AUTOSAR XML (schema 00044)
package /E40_Platform_System_SystemPackage/Components
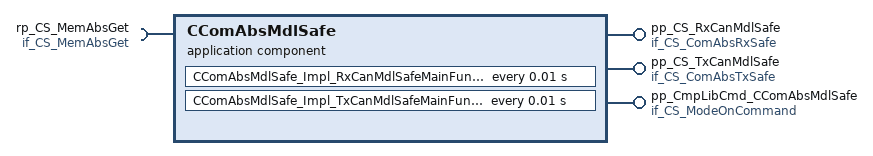
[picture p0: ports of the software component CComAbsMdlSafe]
  application sw component type CComAbsMdlSafe
    provide port pp_CS_RxCanMdlSafe: provided-interface=if_CS_ComAbsRxSafe
      provided-com-specs:
        operation=RxCan_GetSignalValue, queue-length=1
        operation=RxCan_GetSignalValueU8Arr, queue-length=1
        operation=RxCan_SetSignalInitValue, queue-length=1
        operation=RxCan_SetSignalInitValueU8Arr, queue-length=1
        operation=RxCan_SignalClearJustRcvdStatus, queue-length=1
        operation=RxCan_SignalGetJustRcvdStatus, queue-length=1
        operation=RxCan_SignalInvalidProcessingControl, queue-length=1
        operation=RxCan_SignalMissingProcessingControl, queue-length=1
        operation=RxCan_SignalNRProcessingControl, queue-length=1
    provide port pp_CS_TxCanMdlSafe: provided-interface=if_CS_ComAbsTxSafe
      provided-com-specs:
        operation=TxCan_ClearCanSignalTxConfirmation, queue-length=1
        operation=TxCan_GetCanSignalTxConfirmation, queue-length=1
        operation=TxCan_SetSignalFromRetentionBuffer, queue-length=1
        operation=TxCan_SetSignalValue, queue-length=1
        operation=TxCan_SetSignalValueU8Arr, queue-length=1
    provide port pp_CmpLibCmd_CComAbsMdlSafe: server-com-spec{operation=Impl_OnCommand, queue-length=1}, provided-interface=if_CS_ModeOnCommand
    require port rp_CS_MemAbsGet: required-interface=if_CS_MemAbsGet
      required-com-specs:
        Get_BsConst_Audio_Element
        Get_BsConst_Communication_Element
        Get_BsConst_EngOffTimer_Element
        Get_BsConst_FuelGauge_Element
        Get_BsConst_OilGauge_Element
        Get_BsConst_PowerGauge_Element
        Get_BsConst_Power_Element
        Get_BsConst_RealTimeClock_Element
        Get_BsConst_ServiceReminder_Element
        Get_BsConst_SpeedoGauge_Element
        Get_BsConst_TachoGauge_Element
        Get_BsConst_TempGauge_Element
        Get_BsConst_TripComputer_Element
        Get_BsConst_Warning_Element
        Get_BsCys_Certicificate_Element
        Get_BsDiag_Dtc_Element
        Get_BsDiag_ErrorRecord_Element
        Get_BsReten_Audio_Element
        Get_BsReten_Communication_Element
        Get_BsReten_Display_Element
        Get_BsReten_Gauges_Element
        Get_BsReten_Illumination_Element
        Get_BsReten_Odometer_Element
        Get_BsReten_Personalization_Element
        Get_BsReten_Power_Element
        Get_BsReten_RealTimeClock_Element
        Get_BsReten_Tripcomputer_Element
        Get_BsReten_Warning_Element
        Get_BsRt_CusDlt_Element
        Get_BsRt_FuelGauge_Element
        Get_BsRt_Illumination_Element
        Get_BsRt_Odometer_Element
        Get_BsRt_OilGauge_Element
        Get_BsRt_Personalization_Element
        Get_BsRt_PowerGauge_Element
        Get_BsRt_RealTimeClock_Element
        Get_BsRt_SpeedoGauge_Element
        Get_BsRt_TachoGauge_Element
        Get_BsRt_TempGauge_Element
        Get_BsRt_TripComputer_Element
        Get_BsRt_Warning_Element
        Get_BsShare_EcuPartNumber_Element
        Get_BsShare_SwUpdFotaFinPrint_Element
        Get_BsShare_SwUpdFotaMode_Element
        Get_BsShare_SwUpdFotaStatus_Element
        Get_BsShare_SwUpdFotadecrypt_Element
        Get_BsShare_SwUpdReflash_Element
        Get_BsShare_VehicleConfig_Element
        Get_BsShare_VisMeet_Element
        Get_RefCys_Certicificate1_Element
        Get_RefCys_Certicificate_Element
        Get_BsShare_VisMeet_EOLEntry_Element
        Get_BsShare_AssemblyManufacturingDate
        Get_BsShare_AssemblyPlantNumber
        Get_BsShare_HWModification
        Get_BsShare_PCBSerialNumber
        Get_BsShare_ProductSerialNumber
        Get_BsShare_SMTManufacturingDate
        Get_BsShare_SMTPlantNumber
        Get_BsShare_VisteonPCBPartNumber
        Get_BsShare_VisteonPartNumber
        Get_BsConst_BsConst_Illumination_ReservedByte
        Get_BsConst_BsConst_Illumination_ReservedByte_SafeCopy1
        Get_BsConst_BsConst_Illumination_ReservedByte_SafeCopy2
        Get_BsConst_Compensation_Line_Shift_b
        Get_BsConst_Compensation_Line_Shift_b_SafeCopy1
        Get_BsConst_Compensation_Line_Shift_b_SafeCopy2
        Get_BsConst_Compensation_Line_Slope_m
        Get_BsConst_Compensation_Line_Slope_m_SafeCopy1
        Get_BsConst_Compensation_Line_Slope_m_SafeCopy2
        Get_BsConst_Derating_Backlight_Disable
        Get_BsConst_Derating_Backlight_Disable_SafeCopy1
        Get_BsConst_Derating_Backlight_Disable_SafeCopy2
        Get_BsConst_Display_Illum_Max_Level
        Get_BsConst_Display_Illum_Max_Level_SafeCopy1
        Get_BsConst_Display_Illum_Max_Level_SafeCopy2
        Get_BsConst_Lookup_Curve_HotSpot_Coef_X
        Get_BsConst_Lookup_Curve_HotSpot_Coef_X_SafeCopy1
        Get_BsConst_Lookup_Curve_HotSpot_Coef_X_SafeCopy2
        Get_BsConst_Lookup_Curve_HotSpot_Coef_Y
        Get_BsConst_Lookup_Curve_HotSpot_Coef_Y_SafeCopy1
        Get_BsConst_Lookup_Curve_HotSpot_Coef_Y_SafeCopy2
        Get_BsConst_PCB_Temperature_Sensor_Conv
        Get_BsConst_PCB_Temperature_Sensor_Conv_SafeCopy1
        Get_BsConst_PCB_Temperature_Sensor_Conv_SafeCopy2
        Get_BsConst_PWM_boost_bypass_duty
        Get_BsConst_PWM_boost_bypass_duty_SafeCopy1
        Get_BsConst_PWM_boost_bypass_duty_SafeCopy2
        Get_BsConst_Temp_Threshold_Hysteresis_Derating
        Get_BsConst_Temp_Threshold_Hysteresis_Derating_SafeCopy1
        Get_BsConst_Temp_Threshold_Hysteresis_Derating_SafeCopy2
        Get_BsConst_Temperature_Sensor_Conv
        Get_BsConst_Temperature_Sensor_Conv_SafeCopy1
        Get_BsConst_Temperature_Sensor_Conv_SafeCopy2
    behavior IB_CComAbsMdlSafe
      operation invoked event OIE_pp_CmpLibCmd_CComAbsMdlSafe_CComAbsMdlSafe_Impl_OnCommandTrigByImpl_OnCommand: start-on-event=CComAbsMdlSafe_Impl_OnCommand, operation=pp_CmpLibCmd_CComAbsMdlSafe.Impl_OnCommand
      timing event TECComAbsMdlSafe_Impl_RxCanMdlSafeMainFunction: start-on-event=CComAbsMdlSafe_Impl_RxCanMdlSafeMainFunction, period=0.01
      timing event TECComAbsMdlSafe_Impl_TxCanMdlSafeMainFunction: start-on-event=CComAbsMdlSafe_Impl_TxCanMdlSafeMainFunction, period=0.01
      14 x operation invoked event:
        OIE_pp_CS_RxCanMdlSafe_CComAbsMdlSafe_RxCan_GetSignalValueTrigByRxCan_GetSignalValue: start-on-event=CComAbsMdlSafe_RxCan_GetSignalValue, operation=pp_CS_RxCanMdlSafe.RxCan_GetSignalValue
        OIE_pp_CS_RxCanMdlSafe_CComAbsMdlSafe_RxCan_GetSignalValueU8ArrTrigByRxCan_GetSignalValueU8Arr: start-on-event=CComAbsMdlSafe_RxCan_GetSignalValueU8Arr, operation=pp_CS_RxCanMdlSafe.RxCan_GetSignalValueU8Arr
        OIE_pp_CS_RxCanMdlSafe_CComAbsMdlSafe_RxCan_SetSignalInitValueTrigByRxCan_SetSignalInitValue: start-on-event=CComAbsMdlSafe_RxCan_SetSignalInitValue, operation=pp_CS_RxCanMdlSafe.RxCan_SetSignalInitValue
        OIE_pp_CS_RxCanMdlSafe_CComAbsMdlSafe_RxCan_SetSignalInitValueU8ArrTrigByRxCan_SetSignalInitValueU8Arr: start-on-event=CComAbsMdlSafe_RxCan_SetSignalInitValueU8Arr, operation=pp_CS_RxCanMdlSafe.RxCan_SetSignalInitValueU8Arr
        OIE_pp_CS_RxCanMdlSafe_CComAbsMdlSafe_RxCan_SignalClearJustRcvdStatusTrigByRxCan_SignalClearJustRcvdStatus: start-on-event=CComAbsMdlSafe_RxCan_SignalClearJustRcvdStatus, operation=pp_CS_RxCanMdlSafe.RxCan_SignalClearJustRcvdStatus
        OIE_pp_CS_RxCanMdlSafe_CComAbsMdlSafe_RxCan_SignalGetJustRcvdStatusTrigByRxCan_SignalGetJustRcvdStatus: start-on-event=CComAbsMdlSafe_RxCan_SignalGetJustRcvdStatus, operation=pp_CS_RxCanMdlSafe.RxCan_SignalGetJustRcvdStatus
        OIE_pp_CS_RxCanMdlSafe_CComAbsMdlSafe_RxCan_SignalInvalidProcessingControlTrigByRxCan_SignalInvalidProcessingControl: start-on-event=CComAbsMdlSafe_RxCan_SignalInvalidProcessingControl, operation=pp_CS_RxCanMdlSafe.RxCan_SignalInvalidProcessingControl
        OIE_pp_CS_RxCanMdlSafe_CComAbsMdlSafe_RxCan_SignalMissingProcessingControlTrigByRxCan_SignalMissingProcessingControl: start-on-event=CComAbsMdlSafe_RxCan_SignalMissingProcessingControl, operation=pp_CS_RxCanMdlSafe.RxCan_SignalMissingProcessingControl
        OIE_pp_CS_RxCanMdlSafe_CComAbsMdlSafe_RxCan_SignalNRProcessingControlTrigByRxCan_SignalNRProcessingControl: start-on-event=CComAbsMdlSafe_RxCan_SignalNRProcessingControl, operation=pp_CS_RxCanMdlSafe.RxCan_SignalNRProcessingControl
        OIE_pp_CS_TxCanMdlSafe_CComAbsMdlSafe_TxCan_ClearCanSignalTxConfirmationTrigByTxCan_ClearCanSignalTxConfirmation: start-on-event=CComAbsMdlSafe_TxCan_ClearCanSignalTxConfirmation, operation=pp_CS_TxCanMdlSafe.TxCan_ClearCanSignalTxConfirmation
        OIE_pp_CS_TxCanMdlSafe_CComAbsMdlSafe_TxCan_GetCanSignalTxConfirmationTrigByTxCan_GetCanSignalTxConfirmation: start-on-event=CComAbsMdlSafe_TxCan_GetCanSignalTxConfirmation, operation=pp_CS_TxCanMdlSafe.TxCan_GetCanSignalTxConfirmation
        OIE_pp_CS_TxCanMdlSafe_CComAbsMdlSafe_TxCan_SetSignalFromRetentionBufferTrigByTxCan_SetSignalFromRetentionBuffer: start-on-event=CComAbsMdlSafe_TxCan_SetSignalFromRetentionBuffer, operation=pp_CS_TxCanMdlSafe.TxCan_SetSignalFromRetentionBuffer
        OIE_pp_CS_TxCanMdlSafe_CComAbsMdlSafe_TxCan_SetSignalValueTrigByTxCan_SetSignalValue: start-on-event=CComAbsMdlSafe_TxCan_SetSignalValue, operation=pp_CS_TxCanMdlSafe.TxCan_SetSignalValue
        OIE_pp_CS_TxCanMdlSafe_CComAbsMdlSafe_TxCan_SetSignalValueU8ArrTrigByTxCan_SetSignalValueU8Arr: start-on-event=CComAbsMdlSafe_TxCan_SetSignalValueU8Arr, operation=pp_CS_TxCanMdlSafe.TxCan_SetSignalValueU8Arr
      port-api-options:
        enable-take-address=false, error-handling=NO-TRANSFORMER-ERROR-HANDLING, indirect-api=false, port=pp_CS_RxCanMdlSafe
        enable-take-address=false, error-handling=NO-TRANSFORMER-ERROR-HANDLING, indirect-api=false, port=pp_CS_TxCanMdlSafe
        enable-take-address=false, error-handling=NO-TRANSFORMER-ERROR-HANDLING, indirect-api=false, port=pp_CmpLibCmd_CComAbsMdlSafe
        enable-take-address=false, error-handling=NO-TRANSFORMER-ERROR-HANDLING, indirect-api=false, port=rp_CS_MemAbsGet
      17 x runnable, all with can-be-invoked-concurrently=true:
        CComAbsMdlSafe_Impl_OnCommand
          94 x sync call:
            OA_rp_CS_MemAbsGet_Get_BsShare_SwUpdReflash_Element: operation=rp_CS_MemAbsGet.Get_BsShare_SwUpdReflash_Element
            OA_rp_CS_MemAbsGet_Get_BsShare_SwUpdFotaMode_Element: operation=rp_CS_MemAbsGet.Get_BsShare_SwUpdFotaMode_Element
            OA_rp_CS_MemAbsGet_Get_BsShare_SwUpdFotaFinPrint_Element: operation=rp_CS_MemAbsGet.Get_BsShare_SwUpdFotaFinPrint_Element
            OA_rp_CS_MemAbsGet_Get_BsShare_SwUpdFotaStatus_Element: operation=rp_CS_MemAbsGet.Get_BsShare_SwUpdFotaStatus_Element
            OA_rp_CS_MemAbsGet_Get_BsShare_SwUpdFotadecrypt_Element: operation=rp_CS_MemAbsGet.Get_BsShare_SwUpdFotadecrypt_Element
            OA_rp_CS_MemAbsGet_Get_BsShare_EcuPartNumber_Element: operation=rp_CS_MemAbsGet.Get_BsShare_EcuPartNumber_Element
            OA_rp_CS_MemAbsGet_Get_BsShare_VisteonPartNumber: operation=rp_CS_MemAbsGet.Get_BsShare_VisteonPartNumber
            OA_rp_CS_MemAbsGet_Get_BsShare_VisteonPCBPartNumber: operation=rp_CS_MemAbsGet.Get_BsShare_VisteonPCBPartNumber
            OA_rp_CS_MemAbsGet_Get_BsShare_ProductSerialNumber: operation=rp_CS_MemAbsGet.Get_BsShare_ProductSerialNumber
            OA_rp_CS_MemAbsGet_Get_BsShare_PCBSerialNumber: operation=rp_CS_MemAbsGet.Get_BsShare_PCBSerialNumber
            OA_rp_CS_MemAbsGet_Get_BsShare_SMTManufacturingDate: operation=rp_CS_MemAbsGet.Get_BsShare_SMTManufacturingDate
            OA_rp_CS_MemAbsGet_Get_BsShare_AssemblyManufacturingDate: operation=rp_CS_MemAbsGet.Get_BsShare_AssemblyManufacturingDate
            OA_rp_CS_MemAbsGet_Get_BsShare_SMTPlantNumber: operation=rp_CS_MemAbsGet.Get_BsShare_SMTPlantNumber
            OA_rp_CS_MemAbsGet_Get_BsShare_AssemblyPlantNumber: operation=rp_CS_MemAbsGet.Get_BsShare_AssemblyPlantNumber
            OA_rp_CS_MemAbsGet_Get_BsShare_HWModification: operation=rp_CS_MemAbsGet.Get_BsShare_HWModification
            OA_rp_CS_MemAbsGet_Get_BsShare_VisMeet_Element: operation=rp_CS_MemAbsGet.Get_BsShare_VisMeet_Element
            OA_rp_CS_MemAbsGet_Get_BsShare_VisMeet_EOLEntry_Element: operation=rp_CS_MemAbsGet.Get_BsShare_VisMeet_EOLEntry_Element
            OA_rp_CS_MemAbsGet_Get_BsShare_VehicleConfig_Element: operation=rp_CS_MemAbsGet.Get_BsShare_VehicleConfig_Element
            OA_rp_CS_MemAbsGet_Get_BsConst_SpeedoGauge_Element: operation=rp_CS_MemAbsGet.Get_BsConst_SpeedoGauge_Element
            OA_rp_CS_MemAbsGet_Get_BsConst_TachoGauge_Element: operation=rp_CS_MemAbsGet.Get_BsConst_TachoGauge_Element
            OA_rp_CS_MemAbsGet_Get_BsConst_FuelGauge_Element: operation=rp_CS_MemAbsGet.Get_BsConst_FuelGauge_Element
            OA_rp_CS_MemAbsGet_Get_BsConst_TempGauge_Element: operation=rp_CS_MemAbsGet.Get_BsConst_TempGauge_Element
            OA_rp_CS_MemAbsGet_Get_BsConst_PowerGauge_Element: operation=rp_CS_MemAbsGet.Get_BsConst_PowerGauge_Element
            OA_rp_CS_MemAbsGet_Get_BsConst_OilGauge_Element: operation=rp_CS_MemAbsGet.Get_BsConst_OilGauge_Element
            OA_rp_CS_MemAbsGet_Get_BsConst_TripComputer_Element: operation=rp_CS_MemAbsGet.Get_BsConst_TripComputer_Element
            OA_rp_CS_MemAbsGet_Get_BsConst_Compensation_Line_Slope_m: operation=rp_CS_MemAbsGet.Get_BsConst_Compensation_Line_Slope_m
            OA_rp_CS_MemAbsGet_Get_BsConst_Compensation_Line_Shift_b: operation=rp_CS_MemAbsGet.Get_BsConst_Compensation_Line_Shift_b
            OA_rp_CS_MemAbsGet_Get_BsConst_Lookup_Curve_HotSpot_Coef_X: operation=rp_CS_MemAbsGet.Get_BsConst_Lookup_Curve_HotSpot_Coef_X
            OA_rp_CS_MemAbsGet_Get_BsConst_Lookup_Curve_HotSpot_Coef_Y: operation=rp_CS_MemAbsGet.Get_BsConst_Lookup_Curve_HotSpot_Coef_Y
            OA_rp_CS_MemAbsGet_Get_BsConst_Temp_Threshold_Hysteresis_Derating: operation=rp_CS_MemAbsGet.Get_BsConst_Temp_Threshold_Hysteresis_Derating
            OA_rp_CS_MemAbsGet_Get_BsConst_Derating_Backlight_Disable: operation=rp_CS_MemAbsGet.Get_BsConst_Derating_Backlight_Disable
            OA_rp_CS_MemAbsGet_Get_BsConst_Temperature_Sensor_Conv: operation=rp_CS_MemAbsGet.Get_BsConst_Temperature_Sensor_Conv
            OA_rp_CS_MemAbsGet_Get_BsConst_PCB_Temperature_Sensor_Conv: operation=rp_CS_MemAbsGet.Get_BsConst_PCB_Temperature_Sensor_Conv
            OA_rp_CS_MemAbsGet_Get_BsConst_Display_Illum_Max_Level: operation=rp_CS_MemAbsGet.Get_BsConst_Display_Illum_Max_Level
            OA_rp_CS_MemAbsGet_Get_BsConst_PWM_boost_bypass_duty: operation=rp_CS_MemAbsGet.Get_BsConst_PWM_boost_bypass_duty
            OA_rp_CS_MemAbsGet_Get_BsConst_BsConst_Illumination_ReservedByte: operation=rp_CS_MemAbsGet.Get_BsConst_BsConst_Illumination_ReservedByte
            OA_rp_CS_MemAbsGet_Get_BsConst_Compensation_Line_Slope_m_SafeCopy1: operation=rp_CS_MemAbsGet.Get_BsConst_Compensation_Line_Slope_m_SafeCopy1
            OA_rp_CS_MemAbsGet_Get_BsConst_Compensation_Line_Shift_b_SafeCopy1: operation=rp_CS_MemAbsGet.Get_BsConst_Compensation_Line_Shift_b_SafeCopy1
            OA_rp_CS_MemAbsGet_Get_BsConst_Lookup_Curve_HotSpot_Coef_X_SafeCopy1: operation=rp_CS_MemAbsGet.Get_BsConst_Lookup_Curve_HotSpot_Coef_X_SafeCopy1
            OA_rp_CS_MemAbsGet_Get_BsConst_Lookup_Curve_HotSpot_Coef_Y_SafeCopy1: operation=rp_CS_MemAbsGet.Get_BsConst_Lookup_Curve_HotSpot_Coef_Y_SafeCopy1
            OA_rp_CS_MemAbsGet_Get_BsConst_Temp_Threshold_Hysteresis_Derating_SafeCopy1: operation=rp_CS_MemAbsGet.Get_BsConst_Temp_Threshold_Hysteresis_Derating_SafeCopy1
            OA_rp_CS_MemAbsGet_Get_BsConst_Derating_Backlight_Disable_SafeCopy1: operation=rp_CS_MemAbsGet.Get_BsConst_Derating_Backlight_Disable_SafeCopy1
            OA_rp_CS_MemAbsGet_Get_BsConst_Temperature_Sensor_Conv_SafeCopy1: operation=rp_CS_MemAbsGet.Get_BsConst_Temperature_Sensor_Conv_SafeCopy1
            OA_rp_CS_MemAbsGet_Get_BsConst_PCB_Temperature_Sensor_Conv_SafeCopy1: operation=rp_CS_MemAbsGet.Get_BsConst_PCB_Temperature_Sensor_Conv_SafeCopy1
            OA_rp_CS_MemAbsGet_Get_BsConst_Display_Illum_Max_Level_SafeCopy1: operation=rp_CS_MemAbsGet.Get_BsConst_Display_Illum_Max_Level_SafeCopy1
            OA_rp_CS_MemAbsGet_Get_BsConst_PWM_boost_bypass_duty_SafeCopy1: operation=rp_CS_MemAbsGet.Get_BsConst_PWM_boost_bypass_duty_SafeCopy1
            OA_rp_CS_MemAbsGet_Get_BsConst_BsConst_Illumination_ReservedByte_SafeCopy1: operation=rp_CS_MemAbsGet.Get_BsConst_BsConst_Illumination_ReservedByte_SafeCopy1
            OA_rp_CS_MemAbsGet_Get_BsConst_Compensation_Line_Slope_m_SafeCopy2: operation=rp_CS_MemAbsGet.Get_BsConst_Compensation_Line_Slope_m_SafeCopy2
            OA_rp_CS_MemAbsGet_Get_BsConst_Compensation_Line_Shift_b_SafeCopy2: operation=rp_CS_MemAbsGet.Get_BsConst_Compensation_Line_Shift_b_SafeCopy2
            OA_rp_CS_MemAbsGet_Get_BsConst_Lookup_Curve_HotSpot_Coef_X_SafeCopy2: operation=rp_CS_MemAbsGet.Get_BsConst_Lookup_Curve_HotSpot_Coef_X_SafeCopy2
            OA_rp_CS_MemAbsGet_Get_BsConst_Lookup_Curve_HotSpot_Coef_Y_SafeCopy2: operation=rp_CS_MemAbsGet.Get_BsConst_Lookup_Curve_HotSpot_Coef_Y_SafeCopy2
            OA_rp_CS_MemAbsGet_Get_BsConst_Temp_Threshold_Hysteresis_Derating_SafeCopy2: operation=rp_CS_MemAbsGet.Get_BsConst_Temp_Threshold_Hysteresis_Derating_SafeCopy2
            OA_rp_CS_MemAbsGet_Get_BsConst_Derating_Backlight_Disable_SafeCopy2: operation=rp_CS_MemAbsGet.Get_BsConst_Derating_Backlight_Disable_SafeCopy2
            OA_rp_CS_MemAbsGet_Get_BsConst_Temperature_Sensor_Conv_SafeCopy2: operation=rp_CS_MemAbsGet.Get_BsConst_Temperature_Sensor_Conv_SafeCopy2
            OA_rp_CS_MemAbsGet_Get_BsConst_PCB_Temperature_Sensor_Conv_SafeCopy2: operation=rp_CS_MemAbsGet.Get_BsConst_PCB_Temperature_Sensor_Conv_SafeCopy2
            OA_rp_CS_MemAbsGet_Get_BsConst_Display_Illum_Max_Level_SafeCopy2: operation=rp_CS_MemAbsGet.Get_BsConst_Display_Illum_Max_Level_SafeCopy2
            OA_rp_CS_MemAbsGet_Get_BsConst_PWM_boost_bypass_duty_SafeCopy2: operation=rp_CS_MemAbsGet.Get_BsConst_PWM_boost_bypass_duty_SafeCopy2
            OA_rp_CS_MemAbsGet_Get_BsConst_BsConst_Illumination_ReservedByte_SafeCopy2: operation=rp_CS_MemAbsGet.Get_BsConst_BsConst_Illumination_ReservedByte_SafeCopy2
            OA_rp_CS_MemAbsGet_Get_BsConst_Audio_Element: operation=rp_CS_MemAbsGet.Get_BsConst_Audio_Element
            OA_rp_CS_MemAbsGet_Get_BsConst_Warning_Element: operation=rp_CS_MemAbsGet.Get_BsConst_Warning_Element
            OA_rp_CS_MemAbsGet_Get_BsConst_RealTimeClock_Element: operation=rp_CS_MemAbsGet.Get_BsConst_RealTimeClock_Element
            OA_rp_CS_MemAbsGet_Get_BsConst_Communication_Element: operation=rp_CS_MemAbsGet.Get_BsConst_Communication_Element
            OA_rp_CS_MemAbsGet_Get_BsConst_Power_Element: operation=rp_CS_MemAbsGet.Get_BsConst_Power_Element
            OA_rp_CS_MemAbsGet_Get_BsConst_ServiceReminder_Element: operation=rp_CS_MemAbsGet.Get_BsConst_ServiceReminder_Element
            OA_rp_CS_MemAbsGet_Get_BsConst_EngOffTimer_Element: operation=rp_CS_MemAbsGet.Get_BsConst_EngOffTimer_Element
            OA_rp_CS_MemAbsGet_Get_BsCys_Certicificate_Element: operation=rp_CS_MemAbsGet.Get_BsCys_Certicificate_Element
            OA_rp_CS_MemAbsGet_Get_RefCys_Certicificate_Element: operation=rp_CS_MemAbsGet.Get_RefCys_Certicificate_Element
            OA_rp_CS_MemAbsGet_Get_RefCys_Certicificate1_Element: operation=rp_CS_MemAbsGet.Get_RefCys_Certicificate1_Element
            OA_rp_CS_MemAbsGet_Get_BsRt_Odometer_Element: operation=rp_CS_MemAbsGet.Get_BsRt_Odometer_Element
            OA_rp_CS_MemAbsGet_Get_BsRt_SpeedoGauge_Element: operation=rp_CS_MemAbsGet.Get_BsRt_SpeedoGauge_Element
            OA_rp_CS_MemAbsGet_Get_BsRt_TachoGauge_Element: operation=rp_CS_MemAbsGet.Get_BsRt_TachoGauge_Element
            OA_rp_CS_MemAbsGet_Get_BsRt_FuelGauge_Element: operation=rp_CS_MemAbsGet.Get_BsRt_FuelGauge_Element
            OA_rp_CS_MemAbsGet_Get_BsRt_TempGauge_Element: operation=rp_CS_MemAbsGet.Get_BsRt_TempGauge_Element
            OA_rp_CS_MemAbsGet_Get_BsRt_PowerGauge_Element: operation=rp_CS_MemAbsGet.Get_BsRt_PowerGauge_Element
            OA_rp_CS_MemAbsGet_Get_BsRt_OilGauge_Element: operation=rp_CS_MemAbsGet.Get_BsRt_OilGauge_Element
            OA_rp_CS_MemAbsGet_Get_BsRt_TripComputer_Element: operation=rp_CS_MemAbsGet.Get_BsRt_TripComputer_Element
            OA_rp_CS_MemAbsGet_Get_BsRt_Warning_Element: operation=rp_CS_MemAbsGet.Get_BsRt_Warning_Element
            OA_rp_CS_MemAbsGet_Get_BsRt_RealTimeClock_Element: operation=rp_CS_MemAbsGet.Get_BsRt_RealTimeClock_Element
            OA_rp_CS_MemAbsGet_Get_BsRt_Personalization_Element: operation=rp_CS_MemAbsGet.Get_BsRt_Personalization_Element
            OA_rp_CS_MemAbsGet_Get_BsRt_Illumination_Element: operation=rp_CS_MemAbsGet.Get_BsRt_Illumination_Element
            OA_rp_CS_MemAbsGet_Get_BsRt_CusDlt_Element: operation=rp_CS_MemAbsGet.Get_BsRt_CusDlt_Element
            OA_rp_CS_MemAbsGet_Get_BsReten_Odometer_Element: operation=rp_CS_MemAbsGet.Get_BsReten_Odometer_Element
            OA_rp_CS_MemAbsGet_Get_BsReten_Gauges_Element: operation=rp_CS_MemAbsGet.Get_BsReten_Gauges_Element
            OA_rp_CS_MemAbsGet_Get_BsReten_Tripcomputer_Element: operation=rp_CS_MemAbsGet.Get_BsReten_Tripcomputer_Element
            OA_rp_CS_MemAbsGet_Get_BsReten_Illumination_Element: operation=rp_CS_MemAbsGet.Get_BsReten_Illumination_Element
            OA_rp_CS_MemAbsGet_Get_BsReten_Audio_Element: operation=rp_CS_MemAbsGet.Get_BsReten_Audio_Element
            OA_rp_CS_MemAbsGet_Get_BsReten_Warning_Element: operation=rp_CS_MemAbsGet.Get_BsReten_Warning_Element
            OA_rp_CS_MemAbsGet_Get_BsReten_RealTimeClock_Element: operation=rp_CS_MemAbsGet.Get_BsReten_RealTimeClock_Element
            OA_rp_CS_MemAbsGet_Get_BsReten_Communication_Element: operation=rp_CS_MemAbsGet.Get_BsReten_Communication_Element
            OA_rp_CS_MemAbsGet_Get_BsReten_Personalization_Element: operation=rp_CS_MemAbsGet.Get_BsReten_Personalization_Element
            OA_rp_CS_MemAbsGet_Get_BsReten_Power_Element: operation=rp_CS_MemAbsGet.Get_BsReten_Power_Element
            OA_rp_CS_MemAbsGet_Get_BsReten_Display_Element: operation=rp_CS_MemAbsGet.Get_BsReten_Display_Element
            OA_rp_CS_MemAbsGet_Get_BsDiag_ErrorRecord_Element: operation=rp_CS_MemAbsGet.Get_BsDiag_ErrorRecord_Element
            OA_rp_CS_MemAbsGet_Get_BsDiag_Dtc_Element: operation=rp_CS_MemAbsGet.Get_BsDiag_Dtc_Element
        CComAbsMdlSafe_Impl_RxCanMdlSafeMainFunction
          94 x sync call:
            OA_rp_CS_MemAbsGet_Get_BsShare_SwUpdReflash_Element: operation=rp_CS_MemAbsGet.Get_BsShare_SwUpdReflash_Element
            OA_rp_CS_MemAbsGet_Get_BsShare_SwUpdFotaMode_Element: operation=rp_CS_MemAbsGet.Get_BsShare_SwUpdFotaMode_Element
            OA_rp_CS_MemAbsGet_Get_BsShare_SwUpdFotaFinPrint_Element: operation=rp_CS_MemAbsGet.Get_BsShare_SwUpdFotaFinPrint_Element
            OA_rp_CS_MemAbsGet_Get_BsShare_SwUpdFotaStatus_Element: operation=rp_CS_MemAbsGet.Get_BsShare_SwUpdFotaStatus_Element
            OA_rp_CS_MemAbsGet_Get_BsShare_SwUpdFotadecrypt_Element: operation=rp_CS_MemAbsGet.Get_BsShare_SwUpdFotadecrypt_Element
            OA_rp_CS_MemAbsGet_Get_BsShare_EcuPartNumber_Element: operation=rp_CS_MemAbsGet.Get_BsShare_EcuPartNumber_Element
            OA_rp_CS_MemAbsGet_Get_BsShare_VisteonPartNumber: operation=rp_CS_MemAbsGet.Get_BsShare_VisteonPartNumber
            OA_rp_CS_MemAbsGet_Get_BsShare_VisteonPCBPartNumber: operation=rp_CS_MemAbsGet.Get_BsShare_VisteonPCBPartNumber
            OA_rp_CS_MemAbsGet_Get_BsShare_ProductSerialNumber: operation=rp_CS_MemAbsGet.Get_BsShare_ProductSerialNumber
            OA_rp_CS_MemAbsGet_Get_BsShare_PCBSerialNumber: operation=rp_CS_MemAbsGet.Get_BsShare_PCBSerialNumber
            OA_rp_CS_MemAbsGet_Get_BsShare_SMTManufacturingDate: operation=rp_CS_MemAbsGet.Get_BsShare_SMTManufacturingDate
            OA_rp_CS_MemAbsGet_Get_BsShare_AssemblyManufacturingDate: operation=rp_CS_MemAbsGet.Get_BsShare_AssemblyManufacturingDate
            OA_rp_CS_MemAbsGet_Get_BsShare_SMTPlantNumber: operation=rp_CS_MemAbsGet.Get_BsShare_SMTPlantNumber
            OA_rp_CS_MemAbsGet_Get_BsShare_AssemblyPlantNumber: operation=rp_CS_MemAbsGet.Get_BsShare_AssemblyPlantNumber
            OA_rp_CS_MemAbsGet_Get_BsShare_HWModification: operation=rp_CS_MemAbsGet.Get_BsShare_HWModification
            OA_rp_CS_MemAbsGet_Get_BsShare_VisMeet_Element: operation=rp_CS_MemAbsGet.Get_BsShare_VisMeet_Element
            OA_rp_CS_MemAbsGet_Get_BsShare_VisMeet_EOLEntry_Element: operation=rp_CS_MemAbsGet.Get_BsShare_VisMeet_EOLEntry_Element
            OA_rp_CS_MemAbsGet_Get_BsShare_VehicleConfig_Element: operation=rp_CS_MemAbsGet.Get_BsShare_VehicleConfig_Element
            OA_rp_CS_MemAbsGet_Get_BsConst_SpeedoGauge_Element: operation=rp_CS_MemAbsGet.Get_BsConst_SpeedoGauge_Element
            OA_rp_CS_MemAbsGet_Get_BsConst_TachoGauge_Element: operation=rp_CS_MemAbsGet.Get_BsConst_TachoGauge_Element
            OA_rp_CS_MemAbsGet_Get_BsConst_FuelGauge_Element: operation=rp_CS_MemAbsGet.Get_BsConst_FuelGauge_Element
            OA_rp_CS_MemAbsGet_Get_BsConst_TempGauge_Element: operation=rp_CS_MemAbsGet.Get_BsConst_TempGauge_Element
            OA_rp_CS_MemAbsGet_Get_BsConst_PowerGauge_Element: operation=rp_CS_MemAbsGet.Get_BsConst_PowerGauge_Element
            OA_rp_CS_MemAbsGet_Get_BsConst_OilGauge_Element: operation=rp_CS_MemAbsGet.Get_BsConst_OilGauge_Element
            OA_rp_CS_MemAbsGet_Get_BsConst_TripComputer_Element: operation=rp_CS_MemAbsGet.Get_BsConst_TripComputer_Element
            OA_rp_CS_MemAbsGet_Get_BsConst_Compensation_Line_Slope_m: operation=rp_CS_MemAbsGet.Get_BsConst_Compensation_Line_Slope_m
            OA_rp_CS_MemAbsGet_Get_BsConst_Compensation_Line_Shift_b: operation=rp_CS_MemAbsGet.Get_BsConst_Compensation_Line_Shift_b
            OA_rp_CS_MemAbsGet_Get_BsConst_Lookup_Curve_HotSpot_Coef_X: operation=rp_CS_MemAbsGet.Get_BsConst_Lookup_Curve_HotSpot_Coef_X
            OA_rp_CS_MemAbsGet_Get_BsConst_Lookup_Curve_HotSpot_Coef_Y: operation=rp_CS_MemAbsGet.Get_BsConst_Lookup_Curve_HotSpot_Coef_Y
            OA_rp_CS_MemAbsGet_Get_BsConst_Temp_Threshold_Hysteresis_Derating: operation=rp_CS_MemAbsGet.Get_BsConst_Temp_Threshold_Hysteresis_Derating
            OA_rp_CS_MemAbsGet_Get_BsConst_Derating_Backlight_Disable: operation=rp_CS_MemAbsGet.Get_BsConst_Derating_Backlight_Disable
            OA_rp_CS_MemAbsGet_Get_BsConst_Temperature_Sensor_Conv: operation=rp_CS_MemAbsGet.Get_BsConst_Temperature_Sensor_Conv
            OA_rp_CS_MemAbsGet_Get_BsConst_PCB_Temperature_Sensor_Conv: operation=rp_CS_MemAbsGet.Get_BsConst_PCB_Temperature_Sensor_Conv
            OA_rp_CS_MemAbsGet_Get_BsConst_Display_Illum_Max_Level: operation=rp_CS_MemAbsGet.Get_BsConst_Display_Illum_Max_Level
            OA_rp_CS_MemAbsGet_Get_BsConst_PWM_boost_bypass_duty: operation=rp_CS_MemAbsGet.Get_BsConst_PWM_boost_bypass_duty
            OA_rp_CS_MemAbsGet_Get_BsConst_BsConst_Illumination_ReservedByte: operation=rp_CS_MemAbsGet.Get_BsConst_BsConst_Illumination_ReservedByte
            OA_rp_CS_MemAbsGet_Get_BsConst_Compensation_Line_Slope_m_SafeCopy1: operation=rp_CS_MemAbsGet.Get_BsConst_Compensation_Line_Slope_m_SafeCopy1
            OA_rp_CS_MemAbsGet_Get_BsConst_Compensation_Line_Shift_b_SafeCopy1: operation=rp_CS_MemAbsGet.Get_BsConst_Compensation_Line_Shift_b_SafeCopy1
            OA_rp_CS_MemAbsGet_Get_BsConst_Lookup_Curve_HotSpot_Coef_X_SafeCopy1: operation=rp_CS_MemAbsGet.Get_BsConst_Lookup_Curve_HotSpot_Coef_X_SafeCopy1
            OA_rp_CS_MemAbsGet_Get_BsConst_Lookup_Curve_HotSpot_Coef_Y_SafeCopy1: operation=rp_CS_MemAbsGet.Get_BsConst_Lookup_Curve_HotSpot_Coef_Y_SafeCopy1
            OA_rp_CS_MemAbsGet_Get_BsConst_Temp_Threshold_Hysteresis_Derating_SafeCopy1: operation=rp_CS_MemAbsGet.Get_BsConst_Temp_Threshold_Hysteresis_Derating_SafeCopy1
            OA_rp_CS_MemAbsGet_Get_BsConst_Derating_Backlight_Disable_SafeCopy1: operation=rp_CS_MemAbsGet.Get_BsConst_Derating_Backlight_Disable_SafeCopy1
            OA_rp_CS_MemAbsGet_Get_BsConst_Temperature_Sensor_Conv_SafeCopy1: operation=rp_CS_MemAbsGet.Get_BsConst_Temperature_Sensor_Conv_SafeCopy1
            OA_rp_CS_MemAbsGet_Get_BsConst_PCB_Temperature_Sensor_Conv_SafeCopy1: operation=rp_CS_MemAbsGet.Get_BsConst_PCB_Temperature_Sensor_Conv_SafeCopy1
            OA_rp_CS_MemAbsGet_Get_BsConst_Display_Illum_Max_Level_SafeCopy1: operation=rp_CS_MemAbsGet.Get_BsConst_Display_Illum_Max_Level_SafeCopy1
            OA_rp_CS_MemAbsGet_Get_BsConst_PWM_boost_bypass_duty_SafeCopy1: operation=rp_CS_MemAbsGet.Get_BsConst_PWM_boost_bypass_duty_SafeCopy1
            OA_rp_CS_MemAbsGet_Get_BsConst_BsConst_Illumination_ReservedByte_SafeCopy1: operation=rp_CS_MemAbsGet.Get_BsConst_BsConst_Illumination_ReservedByte_SafeCopy1
            OA_rp_CS_MemAbsGet_Get_BsConst_Compensation_Line_Slope_m_SafeCopy2: operation=rp_CS_MemAbsGet.Get_BsConst_Compensation_Line_Slope_m_SafeCopy2
            OA_rp_CS_MemAbsGet_Get_BsConst_Compensation_Line_Shift_b_SafeCopy2: operation=rp_CS_MemAbsGet.Get_BsConst_Compensation_Line_Shift_b_SafeCopy2
            OA_rp_CS_MemAbsGet_Get_BsConst_Lookup_Curve_HotSpot_Coef_X_SafeCopy2: operation=rp_CS_MemAbsGet.Get_BsConst_Lookup_Curve_HotSpot_Coef_X_SafeCopy2
            OA_rp_CS_MemAbsGet_Get_BsConst_Lookup_Curve_HotSpot_Coef_Y_SafeCopy2: operation=rp_CS_MemAbsGet.Get_BsConst_Lookup_Curve_HotSpot_Coef_Y_SafeCopy2
            OA_rp_CS_MemAbsGet_Get_BsConst_Temp_Threshold_Hysteresis_Derating_SafeCopy2: operation=rp_CS_MemAbsGet.Get_BsConst_Temp_Threshold_Hysteresis_Derating_SafeCopy2
            OA_rp_CS_MemAbsGet_Get_BsConst_Derating_Backlight_Disable_SafeCopy2: operation=rp_CS_MemAbsGet.Get_BsConst_Derating_Backlight_Disable_SafeCopy2
            OA_rp_CS_MemAbsGet_Get_BsConst_Temperature_Sensor_Conv_SafeCopy2: operation=rp_CS_MemAbsGet.Get_BsConst_Temperature_Sensor_Conv_SafeCopy2
            OA_rp_CS_MemAbsGet_Get_BsConst_PCB_Temperature_Sensor_Conv_SafeCopy2: operation=rp_CS_MemAbsGet.Get_BsConst_PCB_Temperature_Sensor_Conv_SafeCopy2
            OA_rp_CS_MemAbsGet_Get_BsConst_Display_Illum_Max_Level_SafeCopy2: operation=rp_CS_MemAbsGet.Get_BsConst_Display_Illum_Max_Level_SafeCopy2
            OA_rp_CS_MemAbsGet_Get_BsConst_PWM_boost_bypass_duty_SafeCopy2: operation=rp_CS_MemAbsGet.Get_BsConst_PWM_boost_bypass_duty_SafeCopy2
            OA_rp_CS_MemAbsGet_Get_BsConst_BsConst_Illumination_ReservedByte_SafeCopy2: operation=rp_CS_MemAbsGet.Get_BsConst_BsConst_Illumination_ReservedByte_SafeCopy2
            OA_rp_CS_MemAbsGet_Get_BsConst_Audio_Element: operation=rp_CS_MemAbsGet.Get_BsConst_Audio_Element
            OA_rp_CS_MemAbsGet_Get_BsConst_Warning_Element: operation=rp_CS_MemAbsGet.Get_BsConst_Warning_Element
            OA_rp_CS_MemAbsGet_Get_BsConst_RealTimeClock_Element: operation=rp_CS_MemAbsGet.Get_BsConst_RealTimeClock_Element
            OA_rp_CS_MemAbsGet_Get_BsConst_Communication_Element: operation=rp_CS_MemAbsGet.Get_BsConst_Communication_Element
            OA_rp_CS_MemAbsGet_Get_BsConst_Power_Element: operation=rp_CS_MemAbsGet.Get_BsConst_Power_Element
            OA_rp_CS_MemAbsGet_Get_BsConst_ServiceReminder_Element: operation=rp_CS_MemAbsGet.Get_BsConst_ServiceReminder_Element
            OA_rp_CS_MemAbsGet_Get_BsConst_EngOffTimer_Element: operation=rp_CS_MemAbsGet.Get_BsConst_EngOffTimer_Element
            OA_rp_CS_MemAbsGet_Get_BsCys_Certicificate_Element: operation=rp_CS_MemAbsGet.Get_BsCys_Certicificate_Element
            OA_rp_CS_MemAbsGet_Get_RefCys_Certicificate_Element: operation=rp_CS_MemAbsGet.Get_RefCys_Certicificate_Element
            OA_rp_CS_MemAbsGet_Get_RefCys_Certicificate1_Element: operation=rp_CS_MemAbsGet.Get_RefCys_Certicificate1_Element
            OA_rp_CS_MemAbsGet_Get_BsRt_Odometer_Element: operation=rp_CS_MemAbsGet.Get_BsRt_Odometer_Element
            OA_rp_CS_MemAbsGet_Get_BsRt_SpeedoGauge_Element: operation=rp_CS_MemAbsGet.Get_BsRt_SpeedoGauge_Element
            OA_rp_CS_MemAbsGet_Get_BsRt_TachoGauge_Element: operation=rp_CS_MemAbsGet.Get_BsRt_TachoGauge_Element
            OA_rp_CS_MemAbsGet_Get_BsRt_FuelGauge_Element: operation=rp_CS_MemAbsGet.Get_BsRt_FuelGauge_Element
            OA_rp_CS_MemAbsGet_Get_BsRt_TempGauge_Element: operation=rp_CS_MemAbsGet.Get_BsRt_TempGauge_Element
            OA_rp_CS_MemAbsGet_Get_BsRt_PowerGauge_Element: operation=rp_CS_MemAbsGet.Get_BsRt_PowerGauge_Element
            OA_rp_CS_MemAbsGet_Get_BsRt_OilGauge_Element: operation=rp_CS_MemAbsGet.Get_BsRt_OilGauge_Element
            OA_rp_CS_MemAbsGet_Get_BsRt_TripComputer_Element: operation=rp_CS_MemAbsGet.Get_BsRt_TripComputer_Element
            OA_rp_CS_MemAbsGet_Get_BsRt_Warning_Element: operation=rp_CS_MemAbsGet.Get_BsRt_Warning_Element
            OA_rp_CS_MemAbsGet_Get_BsRt_RealTimeClock_Element: operation=rp_CS_MemAbsGet.Get_BsRt_RealTimeClock_Element
            OA_rp_CS_MemAbsGet_Get_BsRt_Personalization_Element: operation=rp_CS_MemAbsGet.Get_BsRt_Personalization_Element
            OA_rp_CS_MemAbsGet_Get_BsRt_Illumination_Element: operation=rp_CS_MemAbsGet.Get_BsRt_Illumination_Element
            OA_rp_CS_MemAbsGet_Get_BsRt_CusDlt_Element: operation=rp_CS_MemAbsGet.Get_BsRt_CusDlt_Element
            OA_rp_CS_MemAbsGet_Get_BsReten_Odometer_Element: operation=rp_CS_MemAbsGet.Get_BsReten_Odometer_Element
            OA_rp_CS_MemAbsGet_Get_BsReten_Gauges_Element: operation=rp_CS_MemAbsGet.Get_BsReten_Gauges_Element
            OA_rp_CS_MemAbsGet_Get_BsReten_Tripcomputer_Element: operation=rp_CS_MemAbsGet.Get_BsReten_Tripcomputer_Element
            OA_rp_CS_MemAbsGet_Get_BsReten_Illumination_Element: operation=rp_CS_MemAbsGet.Get_BsReten_Illumination_Element
            OA_rp_CS_MemAbsGet_Get_BsReten_Audio_Element: operation=rp_CS_MemAbsGet.Get_BsReten_Audio_Element
            OA_rp_CS_MemAbsGet_Get_BsReten_Warning_Element: operation=rp_CS_MemAbsGet.Get_BsReten_Warning_Element
            OA_rp_CS_MemAbsGet_Get_BsReten_RealTimeClock_Element: operation=rp_CS_MemAbsGet.Get_BsReten_RealTimeClock_Element
            OA_rp_CS_MemAbsGet_Get_BsReten_Communication_Element: operation=rp_CS_MemAbsGet.Get_BsReten_Communication_Element
            OA_rp_CS_MemAbsGet_Get_BsReten_Personalization_Element: operation=rp_CS_MemAbsGet.Get_BsReten_Personalization_Element
            OA_rp_CS_MemAbsGet_Get_BsReten_Power_Element: operation=rp_CS_MemAbsGet.Get_BsReten_Power_Element
            OA_rp_CS_MemAbsGet_Get_BsReten_Display_Element: operation=rp_CS_MemAbsGet.Get_BsReten_Display_Element
            OA_rp_CS_MemAbsGet_Get_BsDiag_ErrorRecord_Element: operation=rp_CS_MemAbsGet.Get_BsDiag_ErrorRecord_Element
            OA_rp_CS_MemAbsGet_Get_BsDiag_Dtc_Element: operation=rp_CS_MemAbsGet.Get_BsDiag_Dtc_Element
        CComAbsMdlSafe_Impl_TxCanMdlSafeMainFunction
        CComAbsMdlSafe_RxCan_GetSignalValue
        CComAbsMdlSafe_RxCan_GetSignalValueU8Arr
        CComAbsMdlSafe_RxCan_SetSignalInitValue
        CComAbsMdlSafe_RxCan_SetSignalInitValueU8Arr
        CComAbsMdlSafe_RxCan_SignalClearJustRcvdStatus
        CComAbsMdlSafe_RxCan_SignalGetJustRcvdStatus
        CComAbsMdlSafe_RxCan_SignalInvalidProcessingControl
        CComAbsMdlSafe_RxCan_SignalMissingProcessingControl
        CComAbsMdlSafe_RxCan_SignalNRProcessingControl
        CComAbsMdlSafe_TxCan_ClearCanSignalTxConfirmation
        CComAbsMdlSafe_TxCan_GetCanSignalTxConfirmation
        CComAbsMdlSafe_TxCan_SetSignalFromRetentionBuffer
        CComAbsMdlSafe_TxCan_SetSignalValue
        CComAbsMdlSafe_TxCan_SetSignalValueU8Arr
  swc implementation IMPL_CComAbsMdlSafe: behavior=IB_CComAbsMdlSafe
